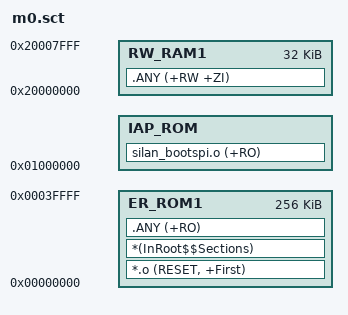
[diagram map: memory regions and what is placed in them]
; *************************************************************
; *** Scatter-Loading Description File generated by uVision ***
; *************************************************************

LR_ROM1 0x0000000 0x00040000  {    ; load region size_region
  ER_ROM1 0x0000000 0x00040000  {  ; load address = execution address
   *.o (RESET, +First)
   *(InRoot$$Sections)
   .ANY (+RO)
  }
  
  IAP_ROM 0x01000000 {
    silan_bootspi.o (+RO)
  }

  RW_RAM1 0x20000000 0x8000  {  ; RW data
   .ANY (+RW +ZI)
  }
}

